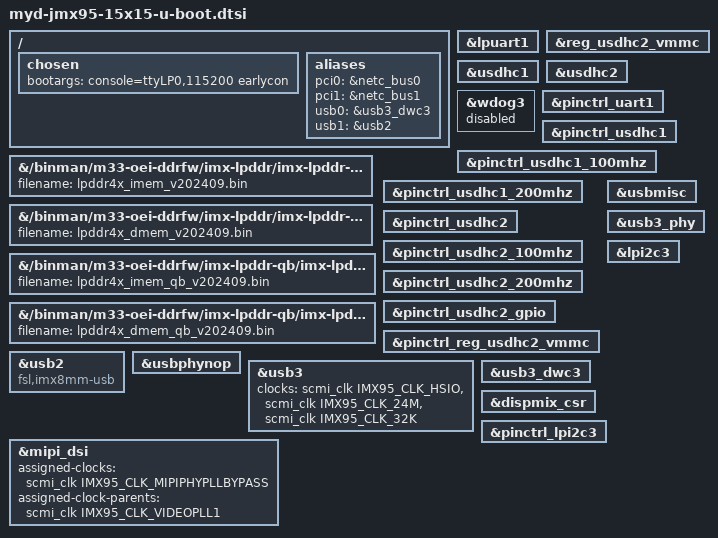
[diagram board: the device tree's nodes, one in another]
// SPDX-License-Identifier: GPL-2.0+
/*
 * Copyright 2026 MYIR
 */

/ {
	chosen {
		bootargs = "console=ttyLP0,115200 earlycon";
	};

	aliases {
		pci0 = &netc_bus0;
		pci1 = &netc_bus1;
		usb0 = &usb3_dwc3;
		usb1 = &usb2;
	};
};

&{/binman/m33-oei-ddrfw/imx-lpddr/imx-lpddr-imem} {
	filename = "lpddr4x_imem_v202409.bin";
};

&{/binman/m33-oei-ddrfw/imx-lpddr/imx-lpddr-dmem} {
	filename = "lpddr4x_dmem_v202409.bin";
};

&{/binman/m33-oei-ddrfw/imx-lpddr-qb/imx-lpddr-imem-qb} {
	filename = "lpddr4x_imem_qb_v202409.bin";
};

&{/binman/m33-oei-ddrfw/imx-lpddr-qb/imx-lpddr-dmem-qb} {
	filename = "lpddr4x_dmem_qb_v202409.bin";
};

&lpuart1 {
	bootph-pre-ram;
};

&reg_usdhc2_vmmc {
	bootph-pre-ram;
};

&usdhc1 {
	bootph-pre-ram;
};

&usdhc2 {
	bootph-pre-ram;
};

&wdog3 {
	status = "disabled";
};

&pinctrl_uart1 {
	bootph-pre-ram;
};

&pinctrl_usdhc1 {
	bootph-pre-ram;
};

&pinctrl_usdhc1_100mhz {
	bootph-pre-ram;
};

&pinctrl_usdhc1_200mhz {
	bootph-pre-ram;
};

&pinctrl_usdhc2 {
	bootph-pre-ram;
};

&pinctrl_usdhc2_100mhz {
	bootph-pre-ram;
};

&pinctrl_usdhc2_200mhz {
	bootph-pre-ram;
};

&pinctrl_usdhc2_gpio {
	bootph-pre-ram;
};

&pinctrl_reg_usdhc2_vmmc {
	bootph-pre-ram;
};

&usb2 {
	compatible = "fsl,imx8mm-usb", "fsl,imx7d-usb";
	/delete-property/power-domains;
	bootph-pre-ram;
};

&usbmisc {
	bootph-pre-ram;
};

&usbphynop {
	bootph-pre-ram;
};

&usb3 {
	clocks = <&scmi_clk IMX95_CLK_HSIO>,
		 <&scmi_clk IMX95_CLK_24M>,
		 <&scmi_clk IMX95_CLK_32K>;
	clock-names = "hsio", "ref", "suspend";
	/delete-property/power-domains;
	bootph-pre-ram;
};

&usb3_phy {
	bootph-pre-ram;
};

&usb3_dwc3 {
	bootph-pre-ram;
};

&dispmix_csr {
	/delete-property/ assigned-clocks;
	/delete-property/ assigned-clock-rates;
	/delete-property/ assigned-clock-parents;
};

&mipi_dsi {
	assigned-clocks = <&scmi_clk IMX95_CLK_MIPIPHYPLLBYPASS>;
	assigned-clock-parents = <&scmi_clk IMX95_CLK_VIDEOPLL1>;
};


&lpi2c3 {
	bootph-some-ram;
};

&pinctrl_lpi2c3 {
	bootph-some-ram;
};
